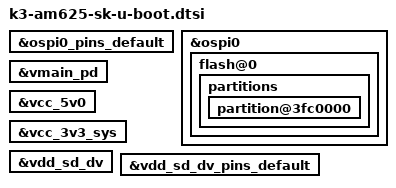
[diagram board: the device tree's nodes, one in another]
// SPDX-License-Identifier: GPL-2.0
/*
 * Common AM625 SK dts file for SPLs
 * Copyright (C) 2021-2022 Texas Instruments Incorporated - https://www.ti.com/
 */

#include "k3-am62x-sk-common-u-boot.dtsi"
#include "k3-am625-sk-binman.dtsi"

&ospi0_pins_default {
	bootph-pre-ram;
};

&ospi0 {
	bootph-pre-ram;

	flash@0 {
		bootph-pre-ram;

		partitions {
			bootph-pre-ram;

			partition@3fc0000 {
				bootph-pre-ram;
			};
		};
	};
};

&vmain_pd {
	bootph-pre-ram;
};

&vcc_5v0 {
	bootph-pre-ram;
};

&vcc_3v3_sys {
	bootph-pre-ram;
};

&vdd_sd_dv {
	bootph-pre-ram;
};

&vdd_sd_dv_pins_default {
	bootph-pre-ram;
};
